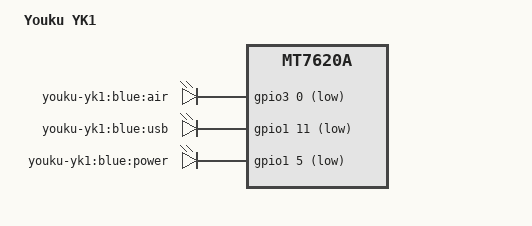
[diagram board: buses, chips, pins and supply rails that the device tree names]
/dts-v1/;

/include/ "YOUKU-YK1.dtsi"

/ {
	compatible = "youku-yk1", "ralink,mt7620a-soc";
	model = "Youku YK1";

	ethernet@10100000 {
		pinctrl-names = "default";
		pinctrl-0 = <&ephy_pins>;
		mtd-mac-address = <&factory 0x4>;
		ralink,port-map = "llllw";
	};

	gpio-leds {
		compatible = "gpio-leds";
		air {
			label = "youku-yk1:blue:air";
			gpios = <&gpio3 0 1>;
		};
		usb {
			label = "youku-yk1:blue:usb";
			gpios = <&gpio1 11 1>;
		};
		power {
			label = "youku-yk1:blue:power";
			gpios = <&gpio1 5 1>;
		};
	};
};
